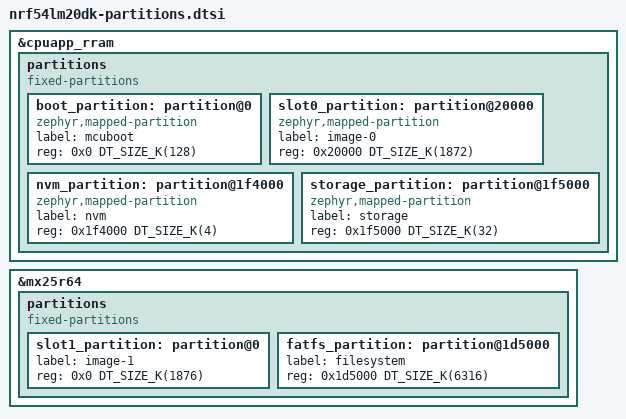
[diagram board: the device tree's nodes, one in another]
/* Partition layout for nrf54lm20dk: the flash memory map shared by the
 * bootloader and every application image. Generated by
 * tools/partition_layout.py; do not edit by hand -- re-run
 * `python3 tools/partition_layout.py --fix nrf54lm20dk` after changing
 * the upstream board geometry or tools/boards.toml.
 *
 * Board-specific overlay glue (delete-nodes, device enablement,
 * aliases/chosen) lives in dts/nordic/nrf54lm20dk.dtsi, which includes
 * this file.
 */

&cpuapp_rram {
	partitions {
		compatible = "fixed-partitions";
		#address-cells = <1>;
		#size-cells = <1>;
		ranges;

		boot_partition: partition@0 {
			compatible = "zephyr,mapped-partition";
			label = "mcuboot";
			reg = <0x0 DT_SIZE_K(128)>;
		};

		slot0_partition: partition@20000 {
			compatible = "zephyr,mapped-partition";
			label = "image-0";
			reg = <0x20000 DT_SIZE_K(1872)>;
		};

		nvm_partition: partition@1f4000 {
			compatible = "zephyr,mapped-partition";
			label = "nvm";
			reg = <0x1f4000 DT_SIZE_K(4)>;
		};

		storage_partition: partition@1f5000 {
			compatible = "zephyr,mapped-partition";
			label = "storage";
			reg = <0x1f5000 DT_SIZE_K(32)>;
		};
	};
};

&mx25r64 {
	partitions {
		compatible = "fixed-partitions";
		#address-cells = <1>;
		#size-cells = <1>;

		slot1_partition: partition@0 {
			label = "image-1";
			reg = <0x0 DT_SIZE_K(1876)>;
		};

		fatfs_partition: partition@1d5000 {
			label = "filesystem";
			reg = <0x1d5000 DT_SIZE_K(6316)>;
		};
	};
};
